# SWM320 register map
File version: 1.0
CPU: CM0 r1p0, little endian, 2 interrupt priority bits
Registers are 32-bit, read-write, no defined reset value unless marked. A register's access mark holds for its fields unless they carry their own. Offsets are from the block's base; [hi:lo] are bit positions; lines under a group give offsets from that group; {n}, {i} and the like mark numbered series; 'fields as' and 'values as' point back to an identical list.

## GPIOA — Registers group
Base 0x40011000
Same registers: GPIOB 0x40012000, GPIOC 0x40013000, GPIOM 0x40015000, GPION 0x40016000, GPIOP 0x40018000
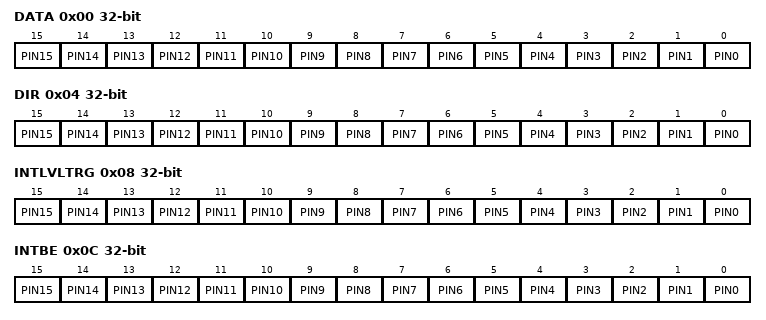
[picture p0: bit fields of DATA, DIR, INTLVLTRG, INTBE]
0x00 DATA
  [n] PIN{n} (n=0..15)
0x04 DIR
  [n] PIN{n} (n=0..15)
0x08 INTLVLTRG
  [n] PIN{n} (n=0..15)
0x0C INTBE
  [n] PIN{n} (n=0..15)
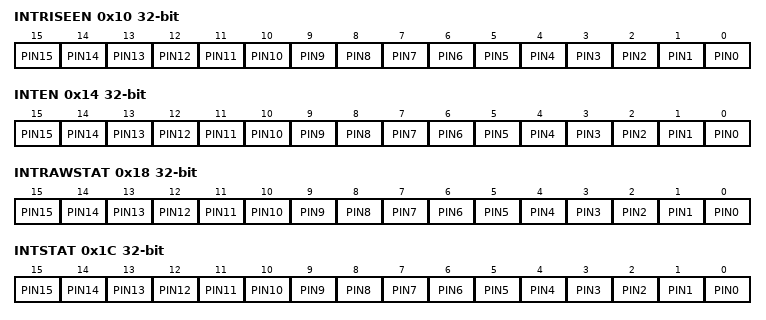
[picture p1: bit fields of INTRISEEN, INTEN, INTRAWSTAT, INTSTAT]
0x10 INTRISEEN
  [n] PIN{n} (n=0..15)
0x14 INTEN
  [n] PIN{n} (n=0..15)
0x18 INTRAWSTAT
  [n] PIN{n} (n=0..15)
0x1C INTSTAT
  [n] PIN{n} (n=0..15)
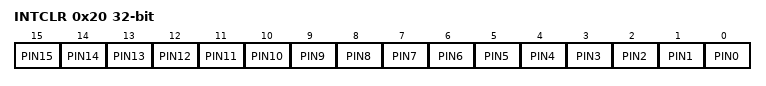
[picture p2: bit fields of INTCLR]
0x20 INTCLR
  [n] PIN{n} (n=0..15)

## TIMR0 — Registers group
Base 0x40017000
Same registers: TIMR1 0x4001700C, TIMR2 0x40017018, TIMR3 0x40017024, TIMR4 0x40017030, TIMR5 0x4001703C
0x00 LDVAL
0x04 CVAL ro
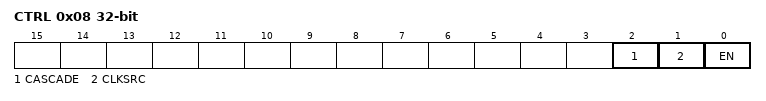
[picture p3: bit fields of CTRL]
0x08 CTRL
  [2] CASCADE, [1] CLKSRC, [0] EN

## TIMRG — Registers group
Base 0x40017060
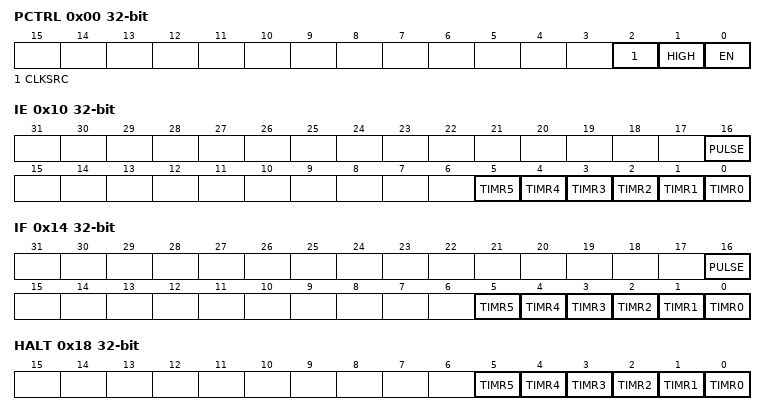
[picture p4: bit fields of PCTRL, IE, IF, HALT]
0x00 PCTRL
  [2] CLKSRC, [1] HIGH, [0] EN
0x04 PCVAL ro
0x10 IE
  [16] PULSE, [n] TIMR{n} (n=0..5)
0x14 IF
  [16] PULSE, [n] TIMR{n} (n=0..5)
0x18 HALT
  [n] TIMR{n} (n=0..5)

## UART0 — Registers group
Base 0x40020000
Same registers: UART1 0x40021000, UART2 0x40022000, UART3 0x40023000
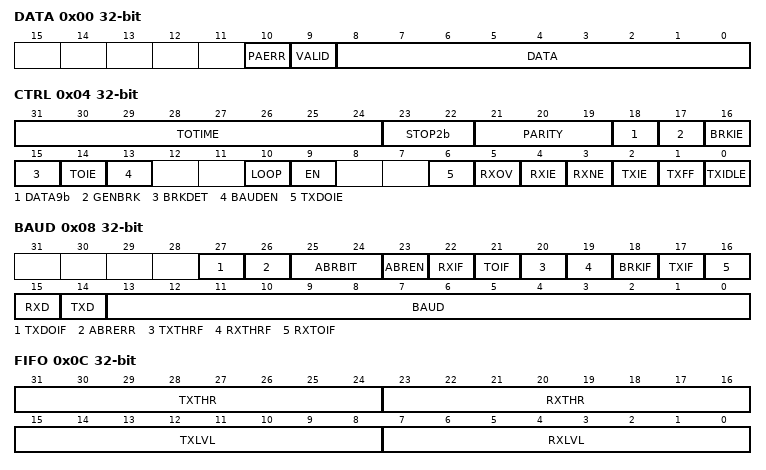
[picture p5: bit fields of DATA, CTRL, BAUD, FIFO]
0x00 DATA
  [10] PAERR, [9] VALID, [8:0] DATA
0x04 CTRL
  [31:24] TOTIME, [23:22] STOP2b, [21:19] PARITY, [18] DATA9b, [17] GENBRK, [16] BRKIE, [15] BRKDET, [14] TOIE, [13] BAUDEN, [10] LOOP, [9] EN, [6] TXDOIE, [5] RXOV, [4] RXIE, [3] RXNE, [2] TXIE, [1] TXFF, [0] TXIDLE
0x08 BAUD
  [27] TXDOIF, [26] ABRERR, [25:24] ABRBIT, [23] ABREN, [22] RXIF, [21] TOIF, [20] TXTHRF, [19] RXTHRF, [18] BRKIF, [17] TXIF, [16] RXTOIF, [15] RXD, [14] TXD, [13:0] BAUD
0x0C FIFO
  [31:24] TXTHR, [23:16] RXTHR, [15:8] TXLVL, [7:0] RXLVL
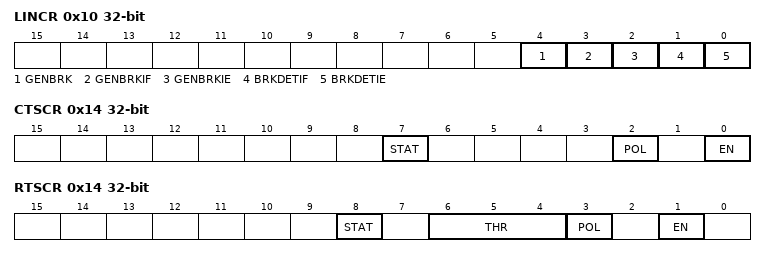
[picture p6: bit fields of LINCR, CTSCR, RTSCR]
0x10 LINCR
  [4] GENBRK, [3] GENBRKIF, [2] GENBRKIE, [1] BRKDETIF, [0] BRKDETIE
0x14 CTSCR
  [7] STAT, [2] POL, [0] EN
0x14 RTSCR (alternate view of CTSCR)
  [8] STAT, [6:4] THR, [3] POL, [1] EN

## SPI0 — Registers group
Base 0x4002C000
Same registers: SPI1 0x4002D000
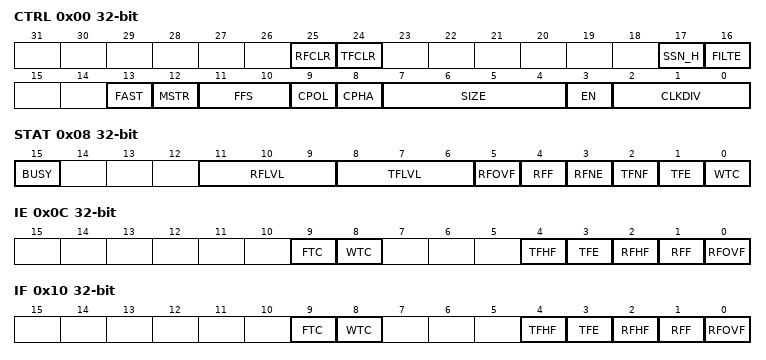
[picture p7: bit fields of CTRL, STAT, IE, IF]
0x00 CTRL
  [25] RFCLR, [24] TFCLR, [17] SSN_H, [16] FILTE, [13] FAST, [12] MSTR, [11:10] FFS, [9] CPOL, [8] CPHA, [7:4] SIZE, [3] EN, [2:0] CLKDIV
0x04 DATA
0x08 STAT
  [15] BUSY, [11:9] RFLVL, [8:6] TFLVL, [5] RFOVF, [4] RFF, [3] RFNE, [2] TFNF, [1] TFE, [0] WTC
0x0C IE
  [9] FTC, [8] WTC, [4] TFHF, [3] TFE, [2] RFHF, [1] RFF, [0] RFOVF
0x10 IF
  [9] FTC, [8] WTC, [4] TFHF, [3] TFE, [2] RFHF, [1] RFF, [0] RFOVF

## I2C0 — Registers group
Base 0x40028000
Same registers: I2C1 0x40029000
0x00 CLKDIV
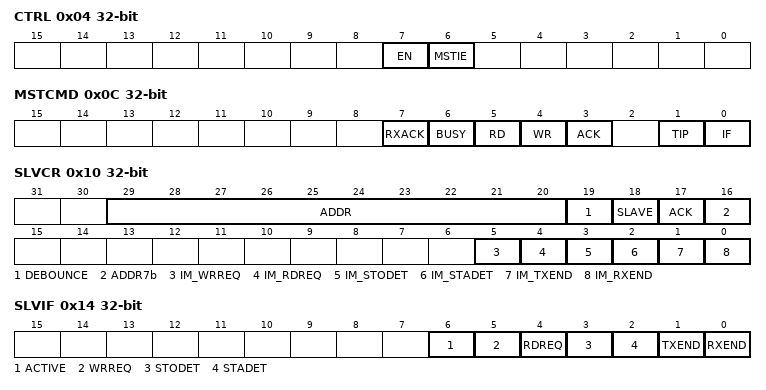
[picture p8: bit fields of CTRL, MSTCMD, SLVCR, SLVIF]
0x04 CTRL
  [7] EN, [6] MSTIE
0x08 MSTDAT
0x0C MSTCMD
  [7] RXACK, [6] BUSY, [5] RD, [4] WR, [3] ACK, [1] TIP, [0] IF
0x10 SLVCR
  [29:20] ADDR, [19] DEBOUNCE, [18] SLAVE, [17] ACK, [16] ADDR7b, [5] IM_WRREQ, [4] IM_RDREQ, [3] IM_STODET, [2] IM_STADET, [1] IM_TXEND, [0] IM_RXEND
0x14 SLVIF
  [6] ACTIVE, [5] WRREQ, [4] RDREQ, [3] STODET, [2] STADET, [1] TXEND, [0] RXEND
0x18 SLVTX
0x1C SLVRX

## ADC0 — Registers group
Base 0x4001C000
Same registers: ADC1 0x4001D000
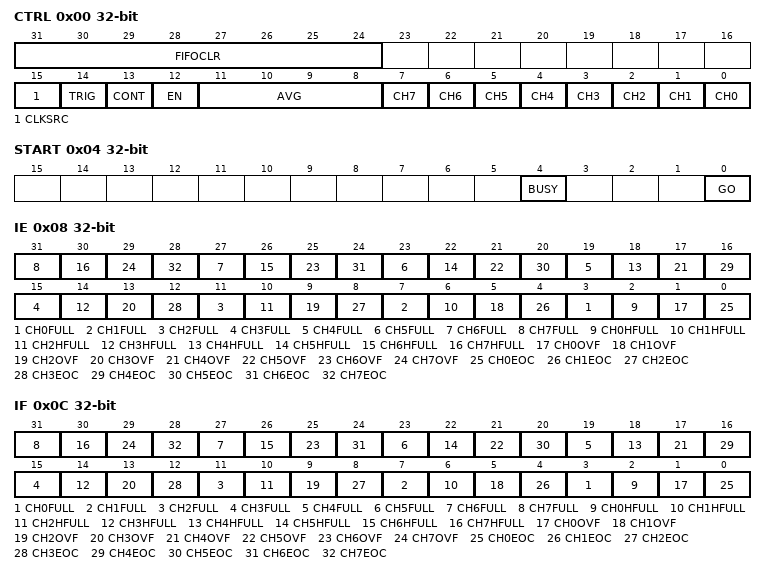
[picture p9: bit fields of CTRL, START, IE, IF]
0x00 CTRL
  [31:24] FIFOCLR, [15] CLKSRC, [14] TRIG, [13] CONT, [12] EN, [11:8] AVG, [n] CH{n} (n=0..7)
0x04 START
  [4] BUSY, [0] GO
0x08 IE
  [4n+3] CH{n}FULL (n=0..7), [4n+2] CH{n}HFULL (n=0..7), [4n+1] CH{n}OVF (n=0..7), [4n] CH{n}EOC (n=0..7)
0x0C IF
  fields as IE
{0x10+0x10*i} CH{i} group (i=0..7) — register cluster
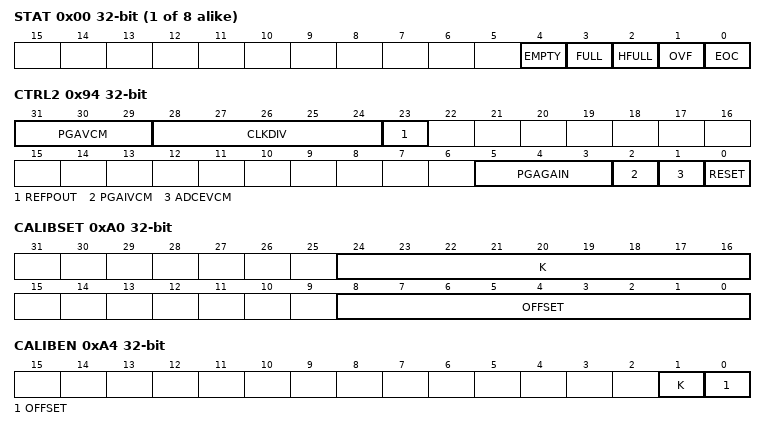
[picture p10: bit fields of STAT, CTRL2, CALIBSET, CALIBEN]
  0x00 STAT
    [4] EMPTY, [3] FULL, [2] HFULL, [1] OVF, [0] EOC
  0x04 DATA
0x90 CTRL1
  [6:4] RIN
0x94 CTRL2
  [31:29] PGAVCM, [28:24] CLKDIV, [23] REFPOUT, [5:3] PGAGAIN, [2] PGAIVCM, [1] ADCEVCM, [0] RESET
0xA0 CALIBSET
  [24:16] K, [8:0] OFFSET
0xA4 CALIBEN
  [1] K, [0] OFFSET

## PWM0 — Registers group
Base 0x4001A000
Same registers: PWM1 0x4001A020, PWM2 0x4001A040, PWM3 0x4001A060, PWM4 0x4001A080, PWM5 0x4001A0A0
0x00 MODE
0x04 PERA
0x08 HIGHA
0x0C DZA
0x10 PERB
0x14 HIGHB
0x18 DZB
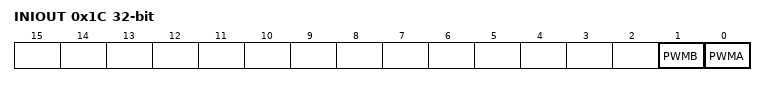
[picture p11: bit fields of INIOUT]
0x1C INIOUT
  [1] PWMB, [0] PWMA
